# RL6955_IP_SVD register map
Vendor: Realtek
Registers are 32-bit, read-write, reset 0x0 unless marked. A register's access mark holds for its fields unless they carry their own. Offsets are from the block's base; [hi:lo] are bit positions; {n}, {i} and the like mark numbered series.

## AES_REG
Base 0x400C0000
0x00 cpu_datain_3 — CPU Data Input register 3
  [31:0] cpu_datain_3 — Input register bit[32*3+31:32*3] of the AES engine in the slave mode, only used in Slave_mode. As input to the engine, such as plaintext or ciphertext, the input order depends on chnx_aes_reg.config.byte_swap bit. If byte_swap = 0, data = {cpu_datain_3[7:0], cpu_datain_3[15:8], cpu_datain_3[23:16], cpu_datain_3[31:24], cpu_datain_2[7:0], cpu_datain_2[15:8], cpu_datain_2[23:16], cpu_datain_2[31:24], cpu_datain_1[7:0], cpu_datain_1[15:8], cpu_datain_1[23:16], cpu_datain_1[31:24], cpu_datain_0[7:0], cpu_datain_0[15:8], cpu_datain_0[23:16], cpu_datain_0[31:24]} If byte_swap = 1, data = {cpu_datain_3, cpu_datain_2, cpu_datain_1, cpu_datain_0} Note that when user starts to write input data, 128bits (4 words) should be written together, that is, user is not allowed to read-write interleave. In other word, no partial write (3 words/2 words/1 words) is allowed, and no read can be inserted between writes.
0x04 cpu_datain_2 — CPU Data Input register 2
  [31:0] cpu_datain_2 — Input register bit[32*2+31:32*2] of the AES engine in the slave mode, only used in Slave_mode. As input to the engine, such as plaintext or ciphertext, the input order depends on chnx_aes_reg.config.byte_swap bit. If byte_swap = 0, data = {cpu_datain_3[7:0], cpu_datain_3[15:8], cpu_datain_3[23:16], cpu_datain_3[31:24], cpu_datain_2[7:0], cpu_datain_2[15:8], cpu_datain_2[23:16], cpu_datain_2[31:24], cpu_datain_1[7:0], cpu_datain_1[15:8], cpu_datain_1[23:16], cpu_datain_1[31:24], cpu_datain_0[7:0], cpu_datain_0[15:8], cpu_datain_0[23:16], cpu_datain_0[31:24]} If byte_swap = 1, data = {cpu_datain_3, cpu_datain_2, cpu_datain_1, cpu_datain_0} Note that when user starts to write input data, 128bits (4 words) should be written together, that is, user is not allowed to read-write interleave. In other word, no partial write (3 words/2 words/1 words) is allowed, and no read can be inserted between writes.
0x08 cpu_datain_1 — CPU Data Input register 1
  [31:0] cpu_datain_1 — Input register bit[32*1+31:32*1] of the AES engine in the slave mode, only used in Slave_mode. As input to the engine, such as plaintext or ciphertext, the input order depends on chnx_aes_reg.config.byte_swap bit. If byte_swap = 0, data = {cpu_datain_3[7:0], cpu_datain_3[15:8], cpu_datain_3[23:16], cpu_datain_3[31:24], cpu_datain_2[7:0], cpu_datain_2[15:8], cpu_datain_2[23:16], cpu_datain_2[31:24], cpu_datain_1[7:0], cpu_datain_1[15:8], cpu_datain_1[23:16], cpu_datain_1[31:24], cpu_datain_0[7:0], cpu_datain_0[15:8], cpu_datain_0[23:16], cpu_datain_0[31:24]} If byte_swap = 1, data = {cpu_datain_3, cpu_datain_2, cpu_datain_1, cpu_datain_0} Note that when user starts to write input data, 128bits (4 words) should be written together, that is, user is not allowed to read-write interleave. In other word, no partial write (3 words/2 words/1 words) is allowed, and no read can be inserted between writes.
0x0C cpu_datain_0 — CPU Data Input register 0
  [31:0] cpu_datain_0 — Input register bit[32*0+31:32*0] of the AES engine in the slave mode, only used in Slave_mode. As input to the engine, such as plaintext or ciphertext, the input order depends on chnx_aes_reg.config.byte_swap bit. If byte_swap = 0, data = {cpu_datain_3[7:0], cpu_datain_3[15:8], cpu_datain_3[23:16], cpu_datain_3[31:24], cpu_datain_2[7:0], cpu_datain_2[15:8], cpu_datain_2[23:16], cpu_datain_2[31:24], cpu_datain_1[7:0], cpu_datain_1[15:8], cpu_datain_1[23:16], cpu_datain_1[31:24], cpu_datain_0[7:0], cpu_datain_0[15:8], cpu_datain_0[23:16], cpu_datain_0[31:24]} If byte_swap = 1, data = {cpu_datain_3, cpu_datain_2, cpu_datain_1, cpu_datain_0} Note that when user starts to write input data, 128bits (4 words) should be written together, that is, user is not allowed to read-write interleave. In other word, no partial write (3 words/2 words/1 words) is allowed, and no read can be inserted between writes.
0x10 cpu_dataout_3 ro — CPU Data Output register 3
  [31:0] cpu_dataout_3 — Output register bit[32*3+31:32*3] of the AES engine in the slave mode, only used in Slave_mode. By waiting for the interrupt or polling the aes_slave_done signal to know whether the AES operation is completed. The result of AES will be stored in this register. The data order depends on chnx_aes_reg.config.byte_swap bit. If byte_swap = 0, rdata = {cpu_dataout_3[7:0], cpu_dataout_3[15:8], cpu_dataout_3[23:16], cpu_dataout_3[31:24], cpu_dataout_2[7:0], cpu_dataout_2[15:8], cpu_dataout_2[23:16], cpu_dataout_2[31:24], cpu_dataout_1[7:0], cpu_dataout_1[15:8], cpu_dataout_1[23:16], cpu_dataout_1[31:24], cpu_dataout_0[7:0], cpu_dataout_0[15:8], cpu_dataout_0[23:16], cpu_dataout_0[31:24]} If byte_swap = 1,r data = {cpu_dataout_3, cpu_dataout_2, cpu_dataout_1, cpu_dataout_0} Note that when user starts to read output data, 128bits (4 words) should be read together, that is, user is not allowed to read-write interleave. In other word, no partial read (3 words/2 words/1 words) is allowed, and no write can be inserted between reads.
0x14 cpu_dataout_2 ro — CPU Data Output register 2
  [31:0] cpu_dataout_2 — Output register bit[32*2+31:32*2] of the AES engine in the slave mode, only used in Slave_mode. By waiting for the interrupt or polling the aes_slave_done signal to know whether the AES operation is completed. The result of AES will be stored in this register. The data order depends on chnx_aes_reg.config.byte_swap bit. If byte_swap = 0, rdata = {cpu_dataout_3[7:0], cpu_dataout_3[15:8], cpu_dataout_3[23:16], cpu_dataout_3[31:24], cpu_dataout_2[7:0], cpu_dataout_2[15:8], cpu_dataout_2[23:16], cpu_dataout_2[31:24], cpu_dataout_1[7:0], cpu_dataout_1[15:8], cpu_dataout_1[23:16], cpu_dataout_1[31:24], cpu_dataout_0[7:0], cpu_dataout_0[15:8], cpu_dataout_0[23:16], cpu_dataout_0[31:24]} If byte_swap = 1,r data = {cpu_dataout_3, cpu_dataout_2, cpu_dataout_1, cpu_dataout_0} Note that when user starts to read output data, 128bits (4 words) should be read together, that is, user is not allowed to read-write interleave. In other word, no partial read (3 words/2 words/1 words) is allowed, and no write can be inserted between reads.
0x18 cpu_dataout_1 ro — CPU Data Output register 1
  [31:0] cpu_dataout_1 — Output register bit[32*1+31:32*1] of the AES engine in the slave mode, only used in Slave_mode. By waiting for the interrupt or polling the aes_slave_done signal to know whether the AES operation is completed. The result of AES will be stored in this register. The data order depends on chnx_aes_reg.config.byte_swap bit. If byte_swap = 0, rdata = {cpu_dataout_3[7:0], cpu_dataout_3[15:8], cpu_dataout_3[23:16], cpu_dataout_3[31:24], cpu_dataout_2[7:0], cpu_dataout_2[15:8], cpu_dataout_2[23:16], cpu_dataout_2[31:24], cpu_dataout_1[7:0], cpu_dataout_1[15:8], cpu_dataout_1[23:16], cpu_dataout_1[31:24], cpu_dataout_0[7:0], cpu_dataout_0[15:8], cpu_dataout_0[23:16], cpu_dataout_0[31:24]} If byte_swap = 1,r data = {cpu_dataout_3, cpu_dataout_2, cpu_dataout_1, cpu_dataout_0} Note that when user starts to read output data, 128bits (4 words) should be read together, that is, user is not allowed to read-write interleave. In other word, no partial read (3 words/2 words/1 words) is allowed, and no write can be inserted between reads.
0x1C cpu_dataout_0 ro — CPU Data Output register 0
  [31:0] cpu_dataout_0 — Output register bit[32*0+31:32*0] of the AES engine in the slave mode, only used in Slave_mode. By waiting for the interrupt or polling the aes_slave_done signal to know whether the AES operation is completed. The result of AES will be stored in this register. The data order depends on chnx_aes_reg.config.byte_swap bit. If byte_swap = 0, rdata = {cpu_dataout_3[7:0], cpu_dataout_3[15:8], cpu_dataout_3[23:16], cpu_dataout_3[31:24], cpu_dataout_2[7:0], cpu_dataout_2[15:8], cpu_dataout_2[23:16], cpu_dataout_2[31:24], cpu_dataout_1[7:0], cpu_dataout_1[15:8], cpu_dataout_1[23:16], cpu_dataout_1[31:24], cpu_dataout_0[7:0], cpu_dataout_0[15:8], cpu_dataout_0[23:16], cpu_dataout_0[31:24]} If byte_swap = 1,r data = {cpu_dataout_3, cpu_dataout_2, cpu_dataout_1, cpu_dataout_0} Note that when user starts to read output data, 128bits (4 words) should be read together, that is, user is not allowed to read-write interleave. In other word, no partial read (3 words/2 words/1 words) is allowed, and no write can be inserted between reads.
0x60 iv_3 — IV register 3
  [31:0] iv_3 — IV register bit[32*3+31:32*3] Except for ECB mode, other modes require IV as input. The user should set the IV before using the AES engine. The IV order depends on chnx_aes_reg.config.byte_swap bit. If byte_swap = 0, iv = {iv_3[7:0], iv_3[15:8], iv_3[23:16], iv_3[31:24], iv_2[7:0], iv_2[15:8], iv_2[23:16], iv_2[31:24], iv_1[7:0], iv_1[15:8], iv_1[23:16], iv_1[31:24], iv_0[7:0], iv_0[15:8], iv_0[23:16], iv_0[31:24]} If byte_swap = 1, iv = {iv_3, iv_2, iv_1, iv_0}
0x64 iv_2 — IV register 2
  [31:0] iv_2 — IV register bit[32*2+31:32*2] Except for ECB mode, other modes require IV as input. The user should set the IV before using the AES engine. The IV order depends on chnx_aes_reg.config.byte_swap bit. If byte_swap = 0, iv = {iv_3[7:0], iv_3[15:8], iv_3[23:16], iv_3[31:24], iv_2[7:0], iv_2[15:8], iv_2[23:16], iv_2[31:24], iv_1[7:0], iv_1[15:8], iv_1[23:16], iv_1[31:24], iv_0[7:0], iv_0[15:8], iv_0[23:16], iv_0[31:24]} If byte_swap = 1, iv = {iv_3, iv_2, iv_1, iv_0}
0x68 iv_1 — IV register 1
  [31:0] iv_1 — IV register bit[32*1+31:32*1] Except for ECB mode, other modes require IV as input. The user should set the IV before using the AES engine. The IV order depends on chnx_aes_reg.config.byte_swap bit. If byte_swap = 0, iv = {iv_3[7:0], iv_3[15:8], iv_3[23:16], iv_3[31:24], iv_2[7:0], iv_2[15:8], iv_2[23:16], iv_2[31:24], iv_1[7:0], iv_1[15:8], iv_1[23:16], iv_1[31:24], iv_0[7:0], iv_0[15:8], iv_0[23:16], iv_0[31:24]} If byte_swap = 1, iv = {iv_3, iv_2, iv_1, iv_0}
0x6C iv_0 — IV register 0
  [31:0] iv_0 — IV register bit[32*0+31:32*0] Except for ECB mode, other modes require IV as input. The user should set the IV before using the AES engine. The IV order depends on chnx_aes_reg.config.byte_swap bit. If byte_swap = 0, iv = {iv_3[7:0], iv_3[15:8], iv_3[23:16], iv_3[31:24], iv_2[7:0], iv_2[15:8], iv_2[23:16], iv_2[31:24], iv_1[7:0], iv_1[15:8], iv_1[23:16], iv_1[31:24], iv_0[7:0], iv_0[15:8], iv_0[23:16], iv_0[31:24]} If byte_swap = 1, iv = {iv_3, iv_2, iv_1, iv_0}
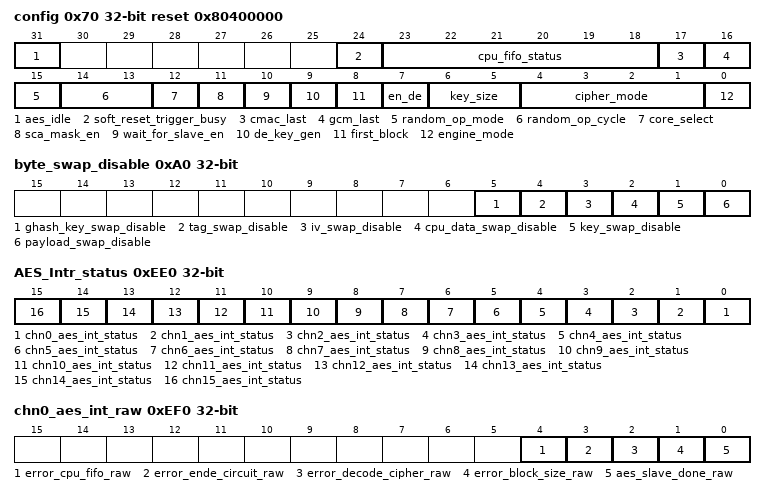
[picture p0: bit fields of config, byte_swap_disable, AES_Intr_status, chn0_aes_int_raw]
0x70 config access per field reset 0x80400000 — Configuration register
  [31] aes_idle ro — When using slave mode to compute gmac and cmac, since the result is a tag, there would be no data in output fifo, therefore, we use this bit to indicate that gmac/cmac has finished (finished means: no input data in input fifo waited to be processed and aes engine has finished all computation)user can polling this bit to check whether aes engine is not running when using GMAC/CMAC.
  [24] soft_reset_trigger_busy rw — Writting 1 to trigger a soft reset. All registers except the mutex register will be reset. Read the bit until 0 to determine if the soft reset is complete.
  [23:18] cpu_fifo_status ro — CPU FIFO status (slave mode FIFO status) {input fifo full (1b), output fifo empty (1b), input data write cnt (2b), output data read cnt (2b)}, for user to check input/output fifo status. When aes_intr asserted (error_cpu_fifo), user can check FIFO status.
  [17] cmac_last rw — Only used in CMAC mode. CMAC mode can be divided into several blocks to calculate. This bit controls whether the last block. If set to 1, it means that the transaction is the last time, and the last block will XOR the subkey.
  [16] gcm_last rw — In some cases, user would need to use slave mode to compute gcm last when all other computations (GMAC) are computed in DMA mode (see Lalu AES GCM Mode). In such cases, user should not set cpu_datain, user should set engine mode to slave mode first and then set gcm_last to trigger AES engine. Note that user should clear this be to zero after calculation.
  [15] random_op_mode ro — Random operation insertion mode. 1: Dynamically insert random cycle of dummy operation in each AES round. 0: Insert fixed cycle (specify by random_op_cycle) of dummy operation in each AES round.
  [14:13] random_op_cycle ro — Random operation cycle. Range from 0~3. 0: Not insert any dummy operation. 1~3: Insert specific cycle of dummy operation.
  [12] core_select rw — Cipher core select. 1: Select SM4 as cipher core 0: Select AES as cipher core
  [11] sca_mask_en rw — SCA mask enable. SW should also set the chn0_sca_mask registers when system initalization. 1: enable SCA protection 0: disable SCA protection
  [10] wait_for_slave_en rw — Pready can be low or always stay high Set to 1: pready will always be 1 Set to 0: pready could be 0 (wait states), default: 0 The difference is that, if set to 1, whenever cpu writes data to input fifo when input fifo is full/read output data from output fifo when output fifo is empty,pready will stay 1, and respond an error (pslverr asserted) immediately. If set to 0, when cpu writes data to input fifo when input fifo is full, however, if there is still space in output fifo, pready will stay 0 untill aes consumes input data from input fifo, that is, there are spaces for incoming input data now. then, pready is asserted, and there will be no error response.When cpu reads data from output fifo when output fifo is empty, however, if there is still available data in input fifo, pready will stay 0 untill aes push output data to output fifo, that is, there is output data waiting to be read now. then, pready is asserted, and there will be no error response.if cpu attempts to write data to input fifo when input is full and output fifo is also full/read data from output fifo when output data is empty and input fifo is also empty, pready will be asserted and respond an error.
  [9] de_key_gen rw — In general, the decryption key will be derived when decrypting in ECB or CBC mode. If the user has prepared the decryption key, can set this register to 0 to skip the cycles of derived. If 1, it will generate a key when decrypting. If 0, it will not generate the key, but instead uses the input to start decrypting.
  [8] first_block rw — If using dma mode, the usage of "first block" is the same as original (before this version). If using slave mode, set "first_block" to 1 is meaningless. that is, it's dont care.When using slave mode, the last step after setting all registers is to set cpu datain. After setting cpu datain (128 bits) in total, AES engine will start computing automatically.(recommend to set to 0 if using slave mode)
  [7] en_de rw — 1'b0: decrypt 1'b1: encrypt
  [6:5] key_size rw — 2'b00: 128 bits 2'b01: 192 bits 2'b10: 256 bits
  [4:1] cipher_mode rw — 4'b0000: ECB mode 4'b0001: CBC mode 4'b0010: CFB mode 4'b0011: OFB mode 4'b0100: CTR mode 4'b0101: GMAC mode (only available when SUPPORT_GCM=1) 4'b0110: GCM mode (only available when SUPPORT_GCM=1) 4'b0111: CMAC mode 4'b1000: XTS mode (only available when SUPPORT_XTS=1)
  [0] engine_mode rw — 0: Slave mode 1: DMA mode
0x74 cipher_len — Input length register
  [31:0] cipher_len — In the CFB, OFB and CTR mode, whether the last block is 16-byte aligned affects the length of the output. In the XTS and CMAC mode, the last block requires additional computation. The user needs to provide the total length for reference. In the GCM mode, the user needs to inform the length of the plaintext or ciphertext. The plaintext or ciphertext does not need to be given at once. But every time add data before the end of the calculation, the user needs to update the data length. Will be used in the last GMAC calculation of GCM.
0x78 gmac_len_1 — AAD length register 1
  [31:0] gmac_len_1 — AAD length register bit[32*1+31:32*1] in GMAC and GCM mode In the GCM or GMAC mode, the user needs to inform the length of the Additional Authenticated Data (AAD). The length of the one AAD needs to be accumulated. Will be used in the last GMAC calculation of GCM.
0x7C gmac_len_0 — AAD length register 0
  [31:0] gmac_len_0 — AAD length register bit[32*0+31:32*0] in GMAC and GCM mode In the GCM or GMAC mode, the user needs to inform the length of the Additional Authenticated Data (AAD). The length of the one AAD needs to be accumulated. Will be used in the last GMAC calculation of GCM.
0x80 tag_3 — Tag register 3
  [31:0] tag_3 — Tag register bit[32*3+31:32*3] After a complete GCM operation, a tag will be generated. The tag will stored in this register. In addition, because GCM can be done in segments, tag can be used as input when GCM is started again. The tag order depends on chnx_aes_reg.config.byte_swap bit. If byte_swap = 0, tag = {tag_3[7:0], tag_3[15:8], tag_3[23:16], tag_3[31:24], tag_2[7:0], tag_2[15:8], tag_2[23:16], tag_2[31:24], tag_1[7:0], tag_1[15:8], tag_1[23:16], tag_1[31:24], tag_0[7:0], tag_0[15:8], tag_0[23:16], tag_0[31:24]} If byte_swap = 1, tag = {tag_3, tag_2, tag_1, tag_0}
0x84 tag_2 — Tag register 2
  [31:0] tag_2 — Tag register bit[32*2+31:32*2] After a complete GCM operation, a tag will be generated. The tag will stored in this register. In addition, because GCM can be done in segments, tag can be used as input when GCM is started again. The tag order depends on chnx_aes_reg.config.byte_swap bit. If byte_swap = 0, tag = {tag_3[7:0], tag_3[15:8], tag_3[23:16], tag_3[31:24], tag_2[7:0], tag_2[15:8], tag_2[23:16], tag_2[31:24], tag_1[7:0], tag_1[15:8], tag_1[23:16], tag_1[31:24], tag_0[7:0], tag_0[15:8], tag_0[23:16], tag_0[31:24]} If byte_swap = 1, tag = {tag_3, tag_2, tag_1, tag_0}
0x88 tag_1 — Tag register 1
  [31:0] tag_1 — Tag register bit[32*1+31:32*1] After a complete GCM operation, a tag will be generated. The tag will stored in this register. In addition, because GCM can be done in segments, tag can be used as input when GCM is started again. The tag order depends on chnx_aes_reg.config.byte_swap bit. If byte_swap = 0, tag = {tag_3[7:0], tag_3[15:8], tag_3[23:16], tag_3[31:24], tag_2[7:0], tag_2[15:8], tag_2[23:16], tag_2[31:24], tag_1[7:0], tag_1[15:8], tag_1[23:16], tag_1[31:24], tag_0[7:0], tag_0[15:8], tag_0[23:16], tag_0[31:24]} If byte_swap = 1, tag = {tag_3, tag_2, tag_1, tag_0}
0x8C tag_0 — Tag register 0
  [31:0] tag_0 — Tag register bit[32*0+31:32*0] After a complete GCM operation, a tag will be generated. The tag will stored in this register. In addition, because GCM can be done in segments, tag can be used as input when GCM is started again. The tag order depends on chnx_aes_reg.config.byte_swap bit. If byte_swap = 0, tag = {tag_3[7:0], tag_3[15:8], tag_3[23:16], tag_3[31:24], tag_2[7:0], tag_2[15:8], tag_2[23:16], tag_2[31:24], tag_1[7:0], tag_1[15:8], tag_1[23:16], tag_1[31:24], tag_0[7:0], tag_0[15:8], tag_0[23:16], tag_0[31:24]} If byte_swap = 1, tag = {tag_3, tag_2, tag_1, tag_0}
0x90 ghash_key_3 — GHASH key register 3
  [31:0] ghash_key_3 — GHASH key register bit[32*3+31:32*3] If using GCM mode without AAD, need to first calculate the ghash key and write it to the register. To generate the ghash key, apply the AES block cipher to the "zero" block with actual key. The ghash_keyorder depends on chnx_aes_reg.config.byte_swap bit. If byte_swap = 0, ghash_key = {ghash_key_3[7:0], ghash_key_3[15:8], ghash_key_3[23:16], ghash_key_3[31:24], ghash_key_2[7:0], ghash_key_2[15:8], ghash_key_2[23:16], ghash_key_2[31:24], ghash_key_1[7:0], ghash_key_1[15:8], ghash_key_1[23:16], ghash_key_1[31:24], ghash_key_0[7:0], ghash_key_0[15:8], ghash_key_0[23:16], ghash_key_0[31:24]} If byte_swap = 1, ghash_key = {ghash_key_3, ghash_key_2, ghash_key_1, ghash_key_0}
0x94 ghash_key_2 — GHASH key register 2
  [31:0] ghash_key_2 — GHASH key register bit[32*2+31:32*2] If using GCM mode without AAD, need to first calculate the ghash key and write it to the register. To generate the ghash key, apply the AES block cipher to the "zero" block with actual key. The ghash_keyorder depends on chnx_aes_reg.config.byte_swap bit. If byte_swap = 0, ghash_key = {ghash_key_3[7:0], ghash_key_3[15:8], ghash_key_3[23:16], ghash_key_3[31:24], ghash_key_2[7:0], ghash_key_2[15:8], ghash_key_2[23:16], ghash_key_2[31:24], ghash_key_1[7:0], ghash_key_1[15:8], ghash_key_1[23:16], ghash_key_1[31:24], ghash_key_0[7:0], ghash_key_0[15:8], ghash_key_0[23:16], ghash_key_0[31:24]} If byte_swap = 1, ghash_key = {ghash_key_3, ghash_key_2, ghash_key_1, ghash_key_0}
0x98 ghash_key_1 — GHASH key register 1
  [31:0] ghash_key_1 — GHASH key register bit[32*1+31:32*1] If using GCM mode without AAD, need to first calculate the ghash key and write it to the register. To generate the ghash key, apply the AES block cipher to the "zero" block with actual key. The ghash_keyorder depends on chnx_aes_reg.config.byte_swap bit. If byte_swap = 0, ghash_key = {ghash_key_3[7:0], ghash_key_3[15:8], ghash_key_3[23:16], ghash_key_3[31:24], ghash_key_2[7:0], ghash_key_2[15:8], ghash_key_2[23:16], ghash_key_2[31:24], ghash_key_1[7:0], ghash_key_1[15:8], ghash_key_1[23:16], ghash_key_1[31:24], ghash_key_0[7:0], ghash_key_0[15:8], ghash_key_0[23:16], ghash_key_0[31:24]} If byte_swap = 1, ghash_key = {ghash_key_3, ghash_key_2, ghash_key_1, ghash_key_0}
0x9C ghash_key_0 — GHASH key register 0
  [31:0] ghash_key_0 — GHASH key register bit[32*0+31:32*0] If using GCM mode without AAD, need to first calculate the ghash key and write it to the register. To generate the ghash key, apply the AES block cipher to the "zero" block with actual key. The ghash_keyorder depends on chnx_aes_reg.config.byte_swap bit. If byte_swap = 0, ghash_key = {ghash_key_3[7:0], ghash_key_3[15:8], ghash_key_3[23:16], ghash_key_3[31:24], ghash_key_2[7:0], ghash_key_2[15:8], ghash_key_2[23:16], ghash_key_2[31:24], ghash_key_1[7:0], ghash_key_1[15:8], ghash_key_1[23:16], ghash_key_1[31:24], ghash_key_0[7:0], ghash_key_0[15:8], ghash_key_0[23:16], ghash_key_0[31:24]} If byte_swap = 1, ghash_key = {ghash_key_3, ghash_key_2, ghash_key_1, ghash_key_0}
0xA0 byte_swap_disable — Byte swap control register
  [5] ghash_key_swap_disable — 1: disable swap ghash_key_x
  [4] tag_swap_disable — 1: disable swap tag_x
  [3] iv_swap_disable — 1: disable swap iv_x
  [2] cpu_data_swap_disable — 1: disable swap cpu_datain_x and cpu_dataout_x
  [1] key_swap_disable — 1: disable swap key_x or key_management input key
  [0] payload_swap_disable — 1: disable swap the data from mem
0xD00 Mutex_status — Engine mutex status register
  [1:0] Engine_mutex_status — If read 0, lock mutex. If not 0, the engine is being used. 2'b01: secure domain lock mutex 2'b10: non-secure domain lock mutex Write 0 to unlock mutex
0xD04 Mutex_overwrite — Engine mutex overwrite register
  [0] Engine_mutex_overwrite — Secure only. Allows secure domain overwrite mutex. 1: enable 0: disable
{0xE00+4i} chn0_sca_mask_{i} wo (i=0..3) — SCA mask reigster {i}
  [31:0] chn0_sca_mask_{i} — Set a SCA mask seed when system initialization. SW should set a random number generated by TRNG to this register every boot.
0xEE0 AES_Intr_status ro — Interrupt status register
  [n] chn{n}_aes_int_status (n=0..15) — Set to 1 when any AES interrupt occurs on channel {n}.
0xEF0 chn0_aes_int_raw ro — Raw interrupt register
  [4] error_cpu_fifo_raw — Set to 1 when the user uses slave mode and writes data when input data fifo is full or reads data when output data fifo is empty. (error condition is related to ctrl.block_pready) *available after version 2024/08/19
  [3] error_ende_circuit_raw — Set to 1 when the user uses the corresponding operation when closing the encryption or decryption circuit.
  [2] error_decode_cipher_raw — Set to 1 when the user sets a non-existent cipher mode.
  [1] error_block_size_raw — Set to 1 when the input size is not a multiple of 128 when using ECB or CBC mode.
  [0] aes_slave_done_raw — Set to 1 when aes has output data waiting for user to read (*after version 2024/08/19)
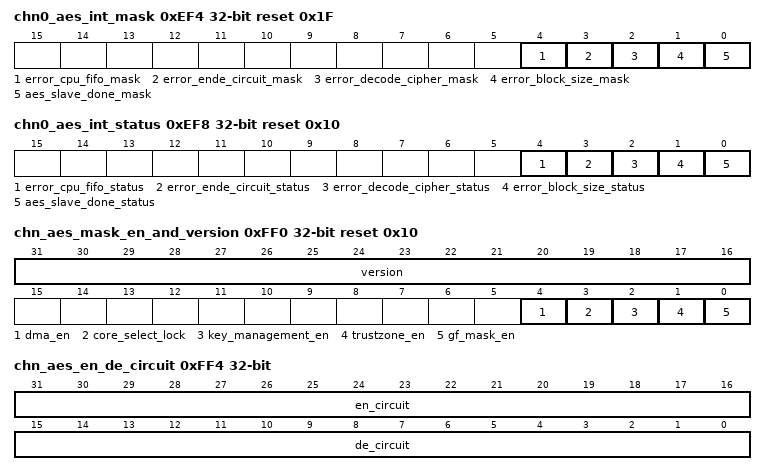
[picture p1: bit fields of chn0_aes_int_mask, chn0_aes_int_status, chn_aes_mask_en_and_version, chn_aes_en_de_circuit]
0xEF4 chn0_aes_int_mask access per field reset 0x1F — Enable interrupt register
  [4] error_cpu_fifo_mask ro — Interrupt error_cpu_fifo enable. *available after version 2024/08/19
  [3] error_ende_circuit_mask rw — Interrupt error_ende_circuit enable.
  [2] error_decode_cipher_mask rw — Interrupt error_decode_cipher enable.
  [1] error_block_size_mask rw — Interrupt error_block_size enable.
  [0] aes_slave_done_mask rw — Interrupt aes_slave_done enable.
0xEF8 chn0_aes_int_status ro reset 0x10 — Masked interrupt register
  [4] error_cpu_fifo_status — Masked error_cpu_fifo *available after version 2024/08/19
  [3] error_ende_circuit_status — Masked error_ende_circuit.
  [2] error_decode_cipher_status — Masked error_decode_cipher.
  [1] error_block_size_status — Masked error_block_size.
  [0] aes_slave_done_status — Masked aes_slave_done.
0xEFC chn0_aes_int_clear wo — Clear interrupt register
  [0] aes_int_clear — Interrupt clear. Writing 1'b1 to the register will trigger a 1-cycle pulse interrupt clear.
0xFF0 chn_aes_mask_en_and_version ro reset 0x10 — Enable AES engine mask status register and version register
  [31:16] version — The lalu_aes version number.
  [4] dma_en — Indicate whether DMA is used (suppoty DMA mode or not)
  [3] core_select_lock — Indicate whether the core_select was locked by hardware pin.
  [2] key_management_en — Indicate whether to use key_management.
  [1] trustzone_en — Indicate whether to use TrustZone.
  [0] gf_mask_en — Indicate whether to use SCA countermeasure.
0xFF4 chn_aes_en_de_circuit ro — Enable circuit status register
  [31:16] en_circuit — Indicate which AES engine has the encryption circuit.
  [15:0] de_circuit — Indicate which AES engine has the decryption circuit.
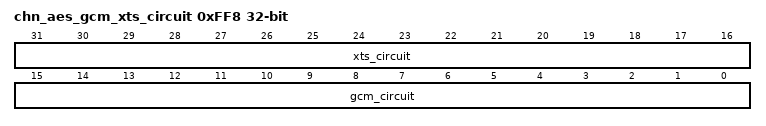
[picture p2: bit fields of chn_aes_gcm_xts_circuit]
0xFF8 chn_aes_gcm_xts_circuit ro — Enable GCM and XTS status register
  [31:16] xts_circuit — Indicate which AES engine has the XTS circuit.
  [15:0] gcm_circuit — Indicate which AES engine has the GCM and GMAC circuit.
0xFFC date ro
  [31:0] date — The date that design was generated.
